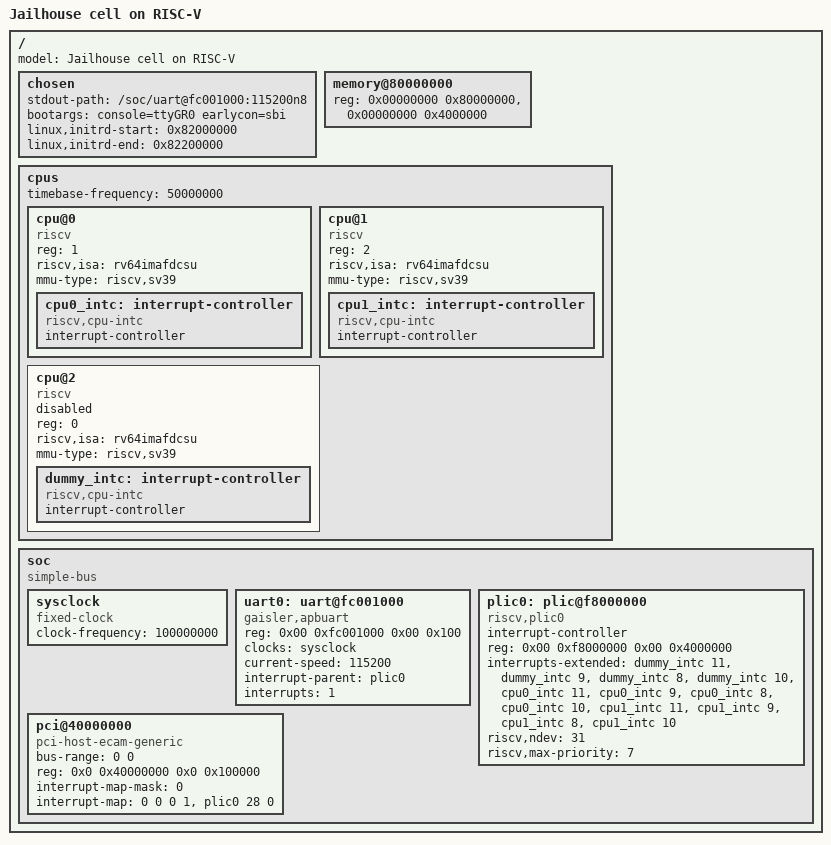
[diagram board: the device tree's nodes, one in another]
/*
 * Jailhouse, a Linux-based partitioning hypervisor
 *
 * Copyright (c) OTH Regensburg, 2022
 *
 * Authors:
 *  Ralf Ramsauer <ralf.ramsauer@oth-regensburg.de>
 *
 * This work is licensed under the terms of the GNU GPL, version 2.  See
 * the COPYING file in the top-level directory.
 */

/dts-v1/;
/ {
	model = "Jailhouse cell on RISC-V";

	#address-cells = <2>;
	#size-cells = <2>;

	chosen {
		stdout-path = "/soc/uart@fc001000:115200n8";
		bootargs = "console=ttyGR0 earlycon=sbi";
		linux,initrd-start = <0x82000000>;
		linux,initrd-end = <0x82200000>;
	};

	memory@80000000 {
		device_type = "memory";
		reg = <0x00000000 0x80000000>, <0x00000000 0x4000000>;
	};

	cpus {
		#address-cells = <1>;
		#size-cells = <0>;
		timebase-frequency = <50000000>;

		cpu@0 {
			device_type = "cpu";
			reg = <1>;
			status = "okay";
			compatible = "riscv";
			riscv,isa = "rv64imafdcsu";
			mmu-type = "riscv,sv39";

			cpu0_intc: interrupt-controller {
				#address-cells = <0>;
				#interrupt-cells = <1>;
				interrupt-controller;
				compatible = "riscv,cpu-intc";
			};
		};

		cpu@1 {
			device_type = "cpu";
			reg = <2>;
			status = "okay";
			compatible = "riscv";
			riscv,isa = "rv64imafdcsu";
			mmu-type = "riscv,sv39";

			cpu1_intc: interrupt-controller {
				#address-cells = <0>;
				#interrupt-cells = <1>;
				interrupt-controller;
				compatible = "riscv,cpu-intc";
			};
		};

		cpu@2 {
			device_type = "cpu";
			reg = <0>;
			status = "disabled";
			compatible = "riscv";
			riscv,isa = "rv64imafdcsu";
			mmu-type = "riscv,sv39";

			dummy_intc: interrupt-controller {
				#address-cells = <0>;
				#interrupt-cells = <1>;
				interrupt-controller;
				compatible = "riscv,cpu-intc";
			};
		};
	};
	soc {
		#address-cells = <2>;
		#size-cells = <2>;
		compatible = "simple-bus";
		ranges;

		sysclock: sysclock {
			#clock-cells = <0>;
			compatible = "fixed-clock";
			clock-frequency = <100000000>;
		};

		uart0: uart@fc001000 {
			compatible = "gaisler,apbuart";
			reg = <0x00 0xfc001000 0x00 0x100>;
			clocks = <&sysclock>;
			current-speed = <115200>;
			interrupt-parent = <&plic0>;
			interrupts = <1>;
		};

		plic0: plic@f8000000 {
			#address-cells = <0x00>;
			#interrupt-cells = <0x01>;
			compatible = "riscv,plic0";
			interrupt-controller;
			reg = <0x00 0xf8000000 0x00 0x4000000>;
			interrupts-extended = <
				&dummy_intc 11
				&dummy_intc 9
				&dummy_intc 8
				&dummy_intc 10
				&cpu0_intc 11
				&cpu0_intc 9
				&cpu0_intc 8
				&cpu0_intc 10
				&cpu1_intc 11
				&cpu1_intc 9
				&cpu1_intc 8
				&cpu1_intc 10
			>;
			riscv,ndev = <31>;
			riscv,max-priority = <7>;
		};

		pci@40000000 {
		        #address-cells = <3>;
		        #size-cells = <2>;
		        #interrupt-cells = <1>;

		        device_type = "pci";
		        bus-range = <0 0>;
		        reg = <0x0 0x40000000 0x0 0x100000>;
		        ranges =  <0x2000000 0x0 0x40100000 0x0 0x40100000  0 0x2000>;

		        interrupt-map-mask = <0>;
		        interrupt-map = <0 0 0 1 &plic0 28 0>;

		        compatible = "pci-host-ecam-generic";
			status = "okay";
		};
	};
};
